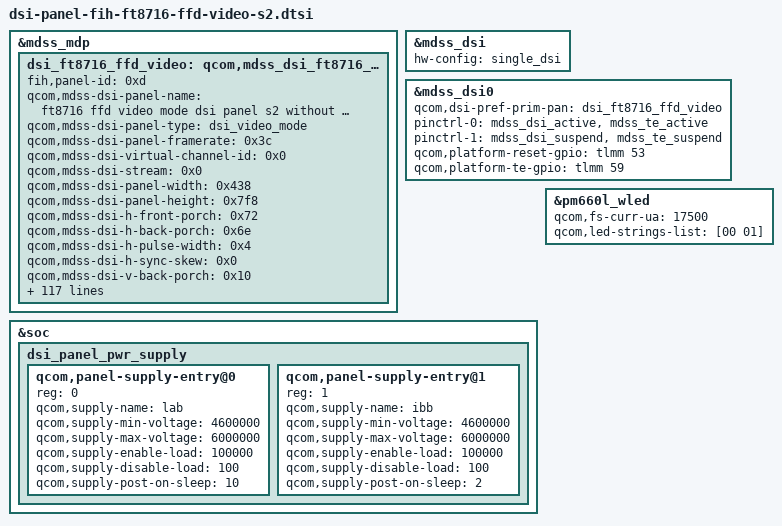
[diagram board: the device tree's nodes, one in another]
/* Copyright (c) 2013, The Linux Foundation. All rights reserved.
 *
 * This program is free software; you can redistribute it and/or modify
 * it under the terms of the GNU General Public License version 2 and
 * only version 2 as published by the Free Software Foundation.
 *
 * This program is distributed in the hope that it will be useful,
 * but WITHOUT ANY WARRANTY; without even the implied warranty of
 * MERCHANTABILITY or FITNESS FOR A PARTICULAR PURPOSE.  See the
 * GNU General Public License for more details.
 */

/*---------------------------------------------------------------------------
 * This file is autogenerated file using gcdb parser. Please do not edit it.
 * Update input XML file to add a new entry or update variable in this file
 * VERSION = "1.0"
 *---------------------------------------------------------------------------*/
&mdss_mdp {
	dsi_ft8716_ffd_video: qcom,mdss_dsi_ft8716_ffd_video_s2 {
		fih,panel-id = <0xd>;
						qcom,mdss-dsi-panel-name = "ft8716 ffd video mode dsi panel s2 without DSC";
				qcom,mdss-dsi-panel-type = "dsi_video_mode";
				qcom,mdss-dsi-panel-framerate = <0x3c>;
				qcom,mdss-dsi-virtual-channel-id = <0x0>;
				qcom,mdss-dsi-stream = <0x0>;
				qcom,mdss-dsi-panel-width = <0x438>;
				qcom,mdss-dsi-panel-height = <0x7f8>;
				qcom,mdss-dsi-h-front-porch = <0x72>;
				qcom,mdss-dsi-h-back-porch = <0x6e>;
				qcom,mdss-dsi-h-pulse-width = <0x4>;
				qcom,mdss-dsi-h-sync-skew = <0x0>;
				qcom,mdss-dsi-v-back-porch = <0x10>;
				qcom,mdss-dsi-v-front-porch = <0x10>;
				qcom,mdss-dsi-v-pulse-width = <0x2>;
				qcom,mdss-dsi-h-left-border = <0x0>;
				qcom,mdss-dsi-h-right-border = <0x0>;
				qcom,mdss-dsi-v-top-border = <0x0>;
				qcom,mdss-dsi-v-bottom-border = <0x0>;
				qcom,mdss-dsi-bpp = <0x18>;
				qcom,mdss-dsi-underflow-color = <0xff>;
				qcom,mdss-dsi-border-color = <0x0>;
				qcom,mdss-dsi-on-command = [29 00 00 00 00 00 04 ff 87 16 01 29 00 00 00 00 00 02 00 80 29 01 00 00 00 00 03 ff 87 16 29 00 00 00 00 00 02 00 80 29 01 00 00 00 00 0d d8 80 81 82 83 85 87 89 8b 8b 8a 89 88 29 00 00 00 00 00 02 00 90 29 01 00 00 00 00 0d d8 00 02 02 03 04 05 06 08 06 06 06 04 29 00 00 00 00 00 02 00 a0 29 01 00 00 00 00 0d d8 00 00 00 00 80 81 81 81 00 01 02 04 29 00 00 00 00 00 02 00 b0 29 01 00 00 00 00 0d d8 00 00 80 80 81 81 82 83 85 87 87 89 29 00 00 00 00 00 02 00 c0 29 01 00 00 00 00 0d d8 85 8d 91 97 a2 ad b9 c3 cd d3 d3 d6 29 00 00 00 00 00 02 00 d0 29 01 00 00 00 00 0d d8 02 05 07 0a 0e 12 16 1b 1e 1e 1e 1f 29 00 00 00 00 00 02 00 e0 29 01 00 00 00 00 04 d8 fc fb e9 29 00 00 00 00 00 02 00 c0 29 01 00 00 00 00 02 d7 41 29 01 00 00 00 00 02 00 a0 29 01 00 00 00 00 02 d7 05 29 00 00 00 00 00 02 00 a0 29 01 00 00 00 00 0d d6 0f 0f 0f 0f 0f 0f 0f 0f 0f 0f 0f 0f 29 00 00 00 00 00 02 00 b0 29 01 00 00 00 00 0d d6 80 80 cd cd cd cd cd cd cd cd cd cd 29 00 00 00 00 00 02 00 c0 29 01 00 00 00 00 0d d6 80 80 b3 b3 b3 b3 b3 b3 b3 b3 b3 b3 29 00 00 00 00 00 02 00 d0 29 01 00 00 00 00 0d d6 80 80 9a 9a 9a 9a 9a 9a 9a 9a 9a 9a 29 00 00 00 00 00 02 00 01 29 00 00 00 00 00 02 c6 10 29 00 00 00 00 00 02 00 00 29 01 00 00 00 00 13 c8 90 78 56 34 33 33 33 33 33 33 43 44 43 44 44 44 44 54 29 00 00 00 00 00 02 00 01 29 00 00 00 00 00 02 c6 11 29 00 00 00 00 00 02 00 00 29 01 00 00 00 00 13 c8 90 78 56 34 33 33 22 33 33 43 44 44 43 44 44 44 44 54 29 00 00 00 00 00 02 00 01 29 00 00 00 00 00 02 c6 12 29 00 00 00 00 00 02 00 00 29 01 00 00 00 00 13 c8 e0 8c 56 33 33 33 33 33 33 33 23 22 33 43 44 44 44 44 29 00 00 00 00 00 02 00 01 29 00 00 00 00 00 02 c6 00 29 00 00 00 00 00 02 00 00 29 01 00 00 00 00 02 92 00 29 00 00 00 00 00 02 00 00 29 01 00 00 00 00 02 94 c4 29 00 00 00 00 00 02 00 00 29 01 00 00 00 00 02 91 80 29 00 00 00 00 00 02 00 00 29 01 00 00 00 00 04 ff 00 00 00 29 00 00 00 00 00 02 00 80 29 00 00 00 00 00 03 ff 00 00 05 01 00 00 78 00 02 11 00 05 01 00 00 0a 00 02 35 00 05 01 00 00 00 00 02 29 00];
				qcom,mdss-dsi-off-command = [05 01 00 00 14 00 02 28 00 05 01 00 00 78 00 02 10 00];
				qcom,mdss-dsi-on-command-state = "dsi_lp_mode";
				qcom,mdss-dsi-off-command-state = "dsi_hs_mode";
				qcom,mdss-dsi-h-sync-pulse = <0x0>;
				qcom,mdss-dsi-traffic-mode = "non_burst_sync_event";
				qcom,mdss-dsi-bllp-eof-power-mode;
				qcom,mdss-dsi-bllp-power-mode;
				qcom,mdss-dsi-lane-0-state;
				qcom,mdss-dsi-lane-1-state;
				qcom,mdss-dsi-lane-2-state;
				qcom,mdss-dsi-lane-3-state;
				qcom,mdss-dsi-t-clk-post = <0xd>;
				qcom,mdss-dsi-t-clk-pre = <0x2d>;
				qcom,esd-check-enabled;
				qcom,mdss-dsi-panel-status-check-mode = "reg_read";
				qcom,mdss-dsi-panel-status-command = <0x6010001 0x10a 0x6010001 0x10b 0x6010001 0x10c 0x6010001 0x10d 0x6010001 0x10e>;
				qcom,mdss-dsi-panel-status-command-state = "dsi_hs_mode";
				qcom,mdss-dsi-panel-status-value = <0x9c 0x0 0x7 0x0 0x80>;
				qcom,mdss-dsi-panel-on-check-value = <0x9c 0x0 0x7 0x0 0x80>;
				qcom,mdss-dsi-panel-status-read-length = <0x1 0x1 0x1 0x1 0x1>;
				qcom,mdss-dsi-panel-max-error-count = <0x3>;
				qcom,mdss-dsi-dma-trigger = "trigger_sw";
				qcom,mdss-dsi-mdp-trigger = "none";
				qcom,mdss-dsi-reset-sequence = <0x1 0x1 0x0 0x1 0x1 0xf>;
				qcom,mdss-dsi-ce-on-command = [29 01 00 00 00 00 03 91 80 00];
				qcom,mdss-dsi-ce-on-command-test1 = [29 01 00 00 00 00 03 91 c0 00];
				qcom,mdss-dsi-ce-on-command-test2 = [29 01 00 00 00 00 03 91 ff 00];
				qcom,mdss-dsi-ce-off-command = [29 01 00 00 00 00 03 91 00 00];
				qcom,mdss-dsi-ct-normal-command = [29 00 00 00 00 00 04 ff 87 16 01 29 00 00 00 00 00 02 00 80 29 01 00 00 00 00 03 ff 87 16 29 00 00 00 00 00 02 00 a0 29 01 00 00 00 00 02 d7 05 29 00 00 00 00 00 02 00 00 29 01 00 00 00 00 02 94 c4 29 00 00 00 00 00 02 00 00 29 00 00 00 00 00 04 ff 00 00 00 29 00 00 00 00 00 02 00 80 29 01 00 00 00 00 03 ff 00 00];
				qcom,mdss-dsi-ct-warm-command = [29 00 00 00 00 00 04 ff 87 16 01 29 00 00 00 00 00 02 00 80 29 01 00 00 00 00 03 ff 87 16 29 00 00 00 00 00 02 00 a0 29 01 00 00 00 00 02 d7 05 29 00 00 00 00 00 02 00 00 29 01 00 00 00 00 02 94 cd 29 00 00 00 00 00 02 00 00 29 00 00 00 00 00 04 ff 00 00 00 29 00 00 00 00 00 02 00 80 29 01 00 00 00 00 03 ff 00 00];
				qcom,mdss-dsi-ct-cold-command = [29 00 00 00 00 00 04 ff 87 16 01 29 00 00 00 00 00 02 00 80 29 01 00 00 00 00 03 ff 87 16 29 00 00 00 00 00 02 00 a0 29 01 00 00 00 00 02 d7 05 29 00 00 00 00 00 02 00 00 29 01 00 00 00 00 02 94 c0 29 00 00 00 00 00 02 00 00 29 00 00 00 00 00 04 ff 00 00 00 29 00 00 00 00 00 02 00 80 29 01 00 00 00 00 03 ff 00 00];
				qcom,mdss-dsi-blf-10-command = [29 00 00 00 00 00 04 ff 87 16 01 29 00 00 00 00 00 02 00 80 29 01 00 00 00 00 03 ff 87 16 29 00 00 00 00 00 02 00 a0 29 01 00 00 00 00 02 d7 05 29 00 00 00 00 00 02 00 00 29 01 00 00 00 00 02 94 c8 29 00 00 00 00 00 02 00 00 29 00 00 00 00 00 04 ff 00 00 00 29 00 00 00 00 00 02 00 80 29 01 00 00 00 00 03 ff 00 00];
				qcom,mdss-dsi-blf-30-command = [29 00 00 00 00 00 04 ff 87 16 01 29 00 00 00 00 00 02 00 80 29 01 00 00 00 00 03 ff 87 16 29 00 00 00 00 00 02 00 a0 29 01 00 00 00 00 02 d7 05 29 00 00 00 00 00 02 00 00 29 01 00 00 00 00 02 94 d5 29 00 00 00 00 00 02 00 00 29 00 00 00 00 00 04 ff 00 00 00 29 00 00 00 00 00 02 00 80 29 01 00 00 00 00 03 ff 00 00];
				qcom,mdss-dsi-blf-50-command = [29 00 00 00 00 00 04 ff 87 16 01 29 00 00 00 00 00 02 00 80 29 01 00 00 00 00 03 ff 87 16 29 00 00 00 00 00 02 00 a0 29 01 00 00 00 00 02 d7 05 29 00 00 00 00 00 02 00 00 29 01 00 00 00 00 02 94 e9 29 00 00 00 00 00 02 00 00 29 00 00 00 00 00 04 ff 00 00 00 29 00 00 00 00 00 02 00 80 29 01 00 00 00 00 03 ff 00 00];
				qcom,mdss-dsi-blf-75-command = [29 00 00 00 00 00 04 ff 87 16 01 29 00 00 00 00 00 02 00 80 29 01 00 00 00 00 03 ff 87 16 29 00 00 00 00 00 02 00 a0 29 01 00 00 00 00 02 d7 05 29 00 00 00 00 00 02 00 00 29 01 00 00 00 00 02 94 ff 29 00 00 00 00 00 02 00 00 29 00 00 00 00 00 04 ff 00 00 00 29 00 00 00 00 00 02 00 80 29 01 00 00 00 00 03 ff 00 00];
				qcom,mdss-dsi-aie-off-command = <0x29000000 0x200 0x290000 0x4 0xff871601 0x29000000 0x200 0x80290100 0x3 0xff871629 0x0 0x20000 0x29010000 0x292 0x290000 0x2 0x2900 0x0 0x4ff0000 0x290000 0x2 0x802901 0x0 0x3ff0000>;
				qcom,mdss-dsi-aie-low-command = <0x29000000 0x200 0x290000 0x4 0xff871601 0x29000000 0x200 0x80290100 0x3 0xff871629 0x0 0x20000 0x29010000 0x292 0x80290000 0x2 0x2900 0x0 0x4ff0000 0x290000 0x2 0x802901 0x0 0x3ff0000>;
				qcom,mdss-dsi-aie-mid-command = <0x29000000 0x200 0x290000 0x4 0xff871601 0x29000000 0x200 0x80290100 0x3 0xff871629 0x0 0x20000 0x29010000 0x292 0x81290000 0x2 0x2900 0x0 0x4ff0000 0x290000 0x2 0x802901 0x0 0x3ff0000>;
				qcom,mdss-dsi-aie-high-command = <0x29000000 0x200 0x290000 0x4 0xff871601 0x29000000 0x200 0x80290100 0x3 0xff871629 0x0 0x20000 0x29010000 0x292 0x82290000 0x2 0x2900 0x0 0x4ff0000 0x290000 0x2 0x802901 0x0 0x3ff0000>;
				qcom,mdss-dsi-ce-on-command-state = "dsi_hs_mode";
				qcom,mdss-dsi-ce-on-command-state-test1 = "dsi_hs_mode";
				qcom,mdss-dsi-ce-on-command-state-test2 = "dsi_hs_mode";
				qcom,mdss-dsi-ce-off-command-state = "dsi_hs_mode";
				qcom,mdss-dsi-ct-normal-command-state = "dsi_lp_mode";
				qcom,mdss-dsi-ct-warm-command-state = "dsi_lp_mode";
				qcom,mdss-dsi-ct-cold-command-state = "dsi_lp_mode";
				qcom,mdss-dsi-blf-10-command-state = "dsi_lp_mode";
				qcom,mdss-dsi-blf-30-command-state = "dsi_lp_mode";
				qcom,mdss-dsi-blf-50-command-state = "dsi_lp_mode";
				qcom,mdss-dsi-blf-75-command-state = "dsi_lp_mode";
				qcom,mdss-dsi-aie-off-command-state = "dsi_lp_mode";
				qcom,mdss-dsi-aie-low-command-state = "dsi_lp_mode";
				qcom,mdss-dsi-aie-mid-command-state = "dsi_lp_mode";
				qcom,mdss-dsi-aie-high-command-state = "dsi_lp_mode";
				qcom,mdss-pan-physical-width-dimension = <0x41>;
				qcom,mdss-pan-physical-height-dimension = <0x7b>;
				qcom,mdss-dsi-panel-timings-phy-v2 = <0x231f0709 0x50304a0 0x231f0709 0x50304a0 0x231f0709 0x50304a0 0x231f0709 0x50304a0 0x23190808 0x50304a0>;
				qcom,mdss-dsi-panel-timings-phy-v2-976 = <0x251f090a 0x60304a0 0x251f090a 0x60304a0 0x251f090a 0x60304a0 0x251f090a 0x60304a0 0x251e080a 0x60304a0>;
				qcom,mdss-dsi-panel-timings-phy-v2-912 = <0x241f0809 0x50304a0 0x241f0809 0x50304a0 0x241f0809 0x50304a0 0x241f0809 0x50304a0 0x241b0809 0x50304a0>;

	};
};

&dsi_ft8716_ffd_video {
	qcom,mdss-dsi-panel-timings-phy-v2 = <0x231f0709 0x50304a0 0x231f0709 0x50304a0 0x231f0709 0x50304a0 0x231f0709 0x50304a0 0x23190808 0x50304a0>;
	qcom,mdss-dsi-panel-timings-phy-v2-976 = <0x251f090a 0x60304a0 0x251f090a 0x60304a0 0x251f090a 0x60304a0 0x251f090a 0x60304a0 0x251e080a 0x60304a0>;
	qcom,mdss-dsi-panel-timings-phy-v2-912 = <0x241f0809 0x50304a0 0x241f0809 0x50304a0 0x241f0809 0x50304a0 0x241f0809 0x50304a0 0x241b0809 0x50304a0>;

	qcom,mdss-dsi-bl-pmic-control-type = "bl_ctrl_wled";
	qcom,mdss-dsi-bl-min-level = <1>;
	qcom,mdss-dsi-bl-max-level = <4095>;
	qcom,panel-supply-entries = <&dsi_panel_pwr_supply>;
};

&mdss_dsi {
	hw-config = "single_dsi";
};

&mdss_dsi0 {
	qcom,dsi-pref-prim-pan = <&dsi_ft8716_ffd_video>;
	pinctrl-names = "mdss_default", "mdss_sleep";
	pinctrl-0 = <&mdss_dsi_active &mdss_te_active>;
	pinctrl-1 = <&mdss_dsi_suspend &mdss_te_suspend>;
	qcom,platform-reset-gpio = <&tlmm 53 0>;
	qcom,platform-te-gpio = <&tlmm 59 0>;
};

&soc {
	/delete-node/dsi_panel_pwr_supply;

	dsi_panel_pwr_supply: dsi_panel_pwr_supply {
		#address-cells = <1>;
		#size-cells = <0>;

		qcom,panel-supply-entry@0 {
			reg = <0>;
			qcom,supply-name = "lab";
			qcom,supply-min-voltage = <4600000>;
			qcom,supply-max-voltage = <6000000>;
			qcom,supply-enable-load = <100000>;
			qcom,supply-disable-load = <100>;
			qcom,supply-post-on-sleep = <10>;
		};

		qcom,panel-supply-entry@1 {
			reg = <1>;
			qcom,supply-name = "ibb";
			qcom,supply-min-voltage = <4600000>;
			qcom,supply-max-voltage = <6000000>;
			qcom,supply-enable-load = <100000>;
			qcom,supply-disable-load = <100>;
			qcom,supply-post-on-sleep = <2>;
		};
	};
};

/*
&msm_ext_disp {
	status = "disabled";
};

&mdss_dp_ctrl {
	status = "disabled";
};
*/

&pm660l_wled {
	qcom,fs-curr-ua = <17500>;
	qcom,led-strings-list = [00 01];
};
